# f28p551x_cpu_sys_regs register map
Vendor: Texas Instruments
Peripheral module from a debugger description file (folder C2000).
Address unit: 16 bits
Registers are 32-bit, read-write, no defined reset value unless marked. A register's access mark holds for its fields unless they carry their own. Offsets are as the file gives them; lines under a group give offsets from that group; [hi:lo] are bit positions; {n}, {i} and the like mark numbered series; 'fields as' and 'values as' point back to an identical list; <NAME> marks a mode.

## CPU_SYS_REGS — CPU SYS Registers
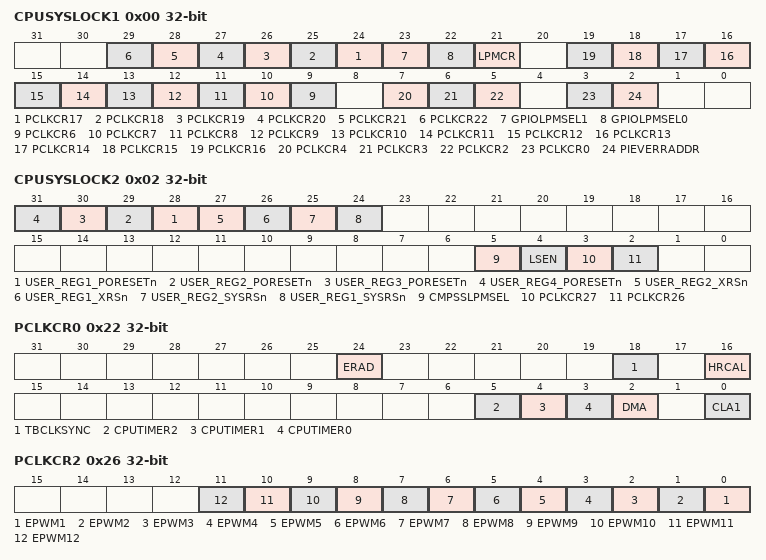
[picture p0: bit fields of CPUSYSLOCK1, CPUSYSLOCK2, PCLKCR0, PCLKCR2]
0x00 CPUSYSLOCK1 — Lock bit for CPUSYS registers
  [n+7] PCLKCR{n} (n=17..22) — Lock bit for PCLKCR{n} Register
  [23] GPIOLPMSEL1 — Lock bit for GPIOLPMSEL1 Register
  [22] GPIOLPMSEL0 — Lock bit for GPIOLPMSEL0 Register
  [21] LPMCR — Lock bit for LPMCR Register
  [n+3] PCLKCR{n} (n=6..16) — Lock bit for PCLKCR{n} Register
  [7] PCLKCR4 — Lock bit for PCLKCR4 Register
  [6] PCLKCR3 — Lock bit for PCLKCR3 Register
  [5] PCLKCR2 — Lock bit for PCLKCR2 Register
  [3] PCLKCR0 — Lock bit for PCLKCR0 Register
  [2] PIEVERRADDR — Lock bit for PIEVERRADDR Register
0x02 CPUSYSLOCK2 — Lock bit for CPUSYS registers
  [n+27] USER_REG{n}_PORESETn (n=1..4) — Lock bit for USER_REG{n}_PORESETn
  [27] USER_REG2_XRSn — Lock bit for USER_REG2_XRSn
  [26] USER_REG1_XRSn — Lock bit for USER_REG1_XRSn
  [25] USER_REG2_SYSRSn — Lock bit for USER_REG2_SYSRSn
  [24] USER_REG1_SYSRSn — Lock bit for USER_REG1_SYSRSn
  [5] CMPSSLPMSEL — Lock bit for CMPSSLPMSEL register
  [4] LSEN — Lock bit for LSEN Register
  [3] PCLKCR27 — Lock bit for PCLKCR27 Register
  [2] PCLKCR26 — Lock bit for PCLKCR26 Register
0x0A PIEVERRADDR — PIE Vector Fetch Error Address register
  [21:0] ADDR — PIE Vector Fetch Error Handler Routine Address
0x22 PCLKCR0 — Peripheral Clock Gating Registers
  [24] ERAD — ERAD module clock enable
  [18] TBCLKSYNC — EPWM Time Base Clock sync
  [16] HRCAL — HRCAL Clock Enable Bit
  [5] CPUTIMER2 — CPUTIMER2 Clock Enable bit
  [4] CPUTIMER1 — CPUTIMER1 Clock Enable bit
  [3] CPUTIMER0 — CPUTIMER0 Clock Enable bit
  [2] DMA — DMA Clock Enable bit
  [0] CLA1 — CLA1 Clock Enable Bit
0x26 PCLKCR2 — Peripheral Clock Gating Register - ETPWM
  [n-1] EPWM{n} (n=1..12) — EPWM{n} Clock Enable bit
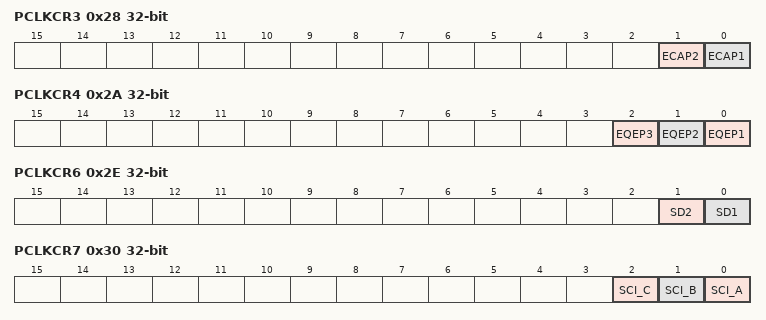
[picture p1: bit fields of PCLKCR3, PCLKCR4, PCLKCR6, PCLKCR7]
0x28 PCLKCR3 — Peripheral Clock Gating Register - ECAP
  [1] ECAP2 — ECAP2 Clock Enable bit
  [0] ECAP1 — ECAP1 Clock Enable bit
0x2A PCLKCR4 — Peripheral Clock Gating Register - EQEP
  [2] EQEP3 — EQEP3 Clock Enable bit
  [1] EQEP2 — EQEP2 Clock Enable bit
  [0] EQEP1 — EQEP1 Clock Enable bit
0x2E PCLKCR6 — Peripheral Clock Gating Register - SDFM
  [1] SD2 — SD2 Clock Enable bit
  [0] SD1 — SD1 Clock Enable bit
0x30 PCLKCR7 — Peripheral Clock Gating Register - SCI
  [2] SCI_C — SCI_C Clock Enable bit
  [1] SCI_B — SCI_B Clock Enable bit
  [0] SCI_A — SCI_A Clock Enable bit
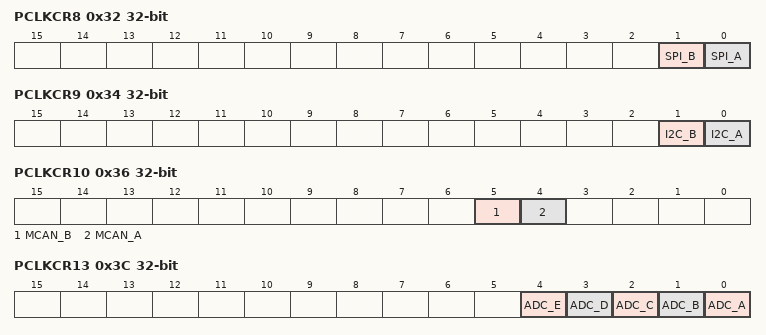
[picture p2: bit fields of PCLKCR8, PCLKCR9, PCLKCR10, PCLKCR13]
0x32 PCLKCR8 — Peripheral Clock Gating Register - SPI
  [1] SPI_B — SPI_B Clock Enable bit
  [0] SPI_A — SPI_A Clock Enable bit
0x34 PCLKCR9 — Peripheral Clock Gating Register - I2C
  [1] I2C_B — I2C_B Clock Enable bit
  [0] I2C_A — I2C_A Clock Enable bit
0x36 PCLKCR10 — Peripheral Clock Gating Register - CAN
  [5] MCAN_B — MCAN_B Clock Enable bit
  [4] MCAN_A — MCAN_A Clock Enable bit
0x38 PCLKCR11 — Peripheral Clock Gating Register - McBSP_USB
  [16] USB_A — USB_A Clock Enable bit
0x3A PCLKCR12 — Peripheral Clock Gating Register - Upp
  [0] NPU — NPU Clock Enable bit
0x3C PCLKCR13 — Peripheral Clock Gating Register - ADC
  [4] ADC_E — ADC_E Clock Enable bit
  [3] ADC_D — ADC_D Clock Enable bit
  [2] ADC_C — ADC_C Clock Enable bit
  [1] ADC_B — ADC_B Clock Enable bit
  [0] ADC_A — ADC_A Clock Enable bit
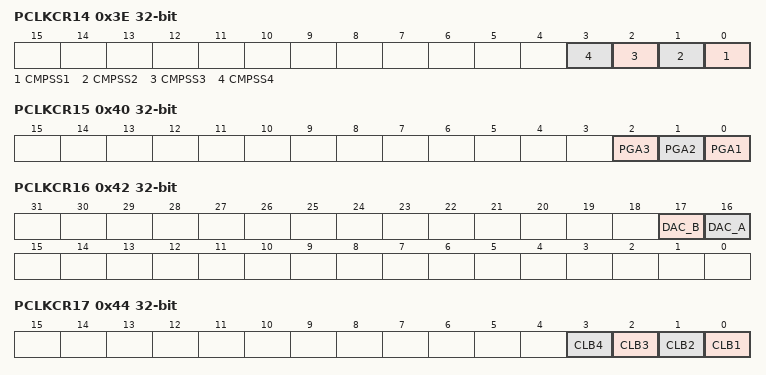
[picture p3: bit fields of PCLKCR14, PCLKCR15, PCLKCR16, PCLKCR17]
0x3E PCLKCR14 — Peripheral Clock Gating Register - CMPSS
  [n-1] CMPSS{n} (n=1..4) — CMPSS{n} Clock Enable bit
0x40 PCLKCR15 — Peripheral Clock Gating Register - PGA
  [2] PGA3 — PGA3 Clock Enable bit
  [1] PGA2 — PGA2 Clock Enable bit
  [0] PGA1 — PGA1 Clock Enable bit
0x42 PCLKCR16 — Peripheral Clock Gating Register Buf_DAC
  [17] DAC_B — Buffered_DAC_B Clock Enable Bit
  [16] DAC_A — Buffered_DAC_A Clock Enable Bit
0x44 PCLKCR17 — Peripheral Clock Gating Register - CLB
  [n-1] CLB{n} (n=1..4) — CLB{n} Clock Enable bit
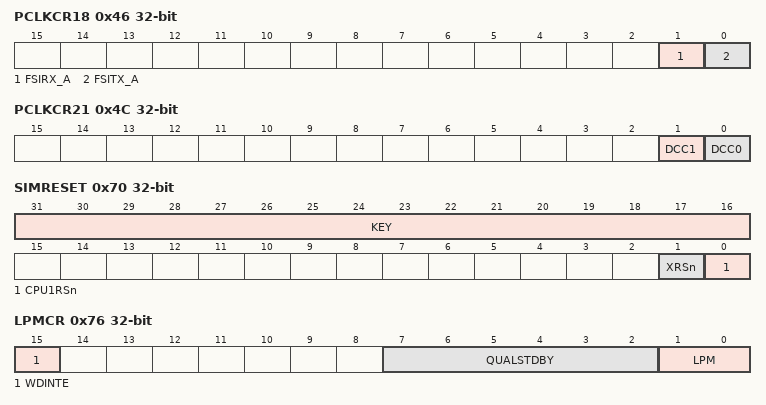
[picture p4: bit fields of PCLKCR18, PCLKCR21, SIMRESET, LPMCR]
0x46 PCLKCR18 — Peripheral Clock Gating Register - FSI
  [1] FSIRX_A — FSIRX_A Clock Enable bit
  [0] FSITX_A — FSITX_A Clock Enable bit
0x48 PCLKCR19 — Peripheral Clock Gating Register - LIN
  [0] LIN_A — LIN_A Clock Enable bit
0x4A PCLKCR20 — Peripheral Clock Gating Register - PMBUS
  [0] PMBUS_A — PMBUS_A Clock Enable bit
0x4C PCLKCR21 — Peripheral Clock Gating Register - DCC
  [1] DCC1 — DCC1 Clock Enable Bit
  [0] DCC0 — DCC0 Clock Enable Bit
0x56 PCLKCR26 — Peripheral Clock Gating Register - AES
  [0] AESA — AESA Clock Enable Bit
0x58 PCLKCR27 — Peripheral Clock Gating Register - EPG
  [0] EPG1 — EPG1 Clock Enable Bit
0x70 SIMRESET — Simulated Reset Register
  [31:16] KEY — Key value to enable write
  [1] XRSn — Generates a simulated XRSn
  [0] CPU1RSn — Generates a reset to CPU
0x76 LPMCR — LPM Control Register
  [15] WDINTE — Enable for WDINT wakeup from STANDBY
  [7:2] QUALSTDBY — STANDBY Wakeup Pin Qualification Setting
  [1:0] LPM — Low Power Mode setting
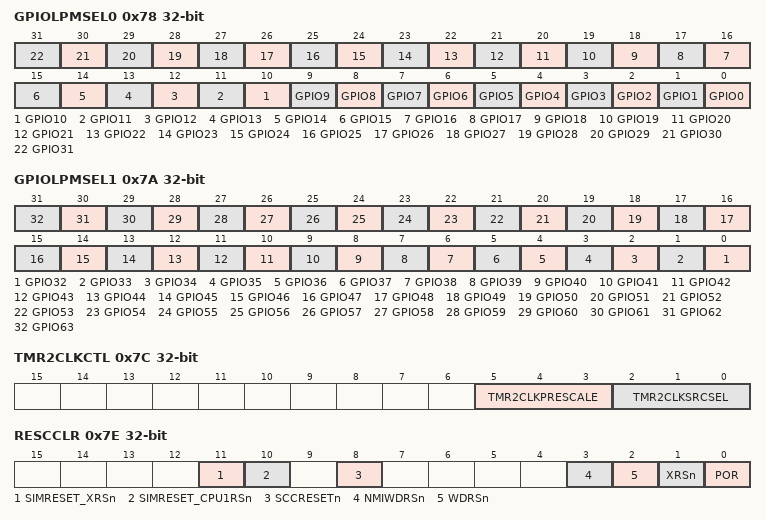
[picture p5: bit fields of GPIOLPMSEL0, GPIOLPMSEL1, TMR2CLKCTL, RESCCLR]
0x78 GPIOLPMSEL0 — GPIO LPM Wakeup select registers
  [n] GPIO{n} (n=0..31) — GPIO{n} Enable for LPM Wakeup
0x7A GPIOLPMSEL1 — GPIO LPM Wakeup select registers
  [n-32] GPIO{n} (n=32..63) — GPIO{n} Enable for LPM Wakeup
0x7C TMR2CLKCTL — Timer2 Clock Measurement functionality control register
  [5:3] TMR2CLKPRESCALE — CPU Timer 2 Clock Pre-Scale Value
  [2:0] TMR2CLKSRCSEL — CPU Timer 2 Clock Source Select Bit
0x7E RESCCLR — Reset Cause Clear Register
  [11] SIMRESET_XRSn — SIMRESET_XRSn Reset Cause Indication Bit
  [10] SIMRESET_CPU1RSn — SIMRESET_CPU1RSn Reset Cause Indication Bit
  [8] SCCRESETn — SCCRESETn Reset Cause Indication Bit
  [3] NMIWDRSn — NMIWDRSn Reset Cause Indication Bit
  [2] WDRSn — WDRSn Reset Cause Indication Bit
  [1] XRSn — XRSn Reset Cause Indication Bit
  [0] POR — POR Reset Cause Indication Bit
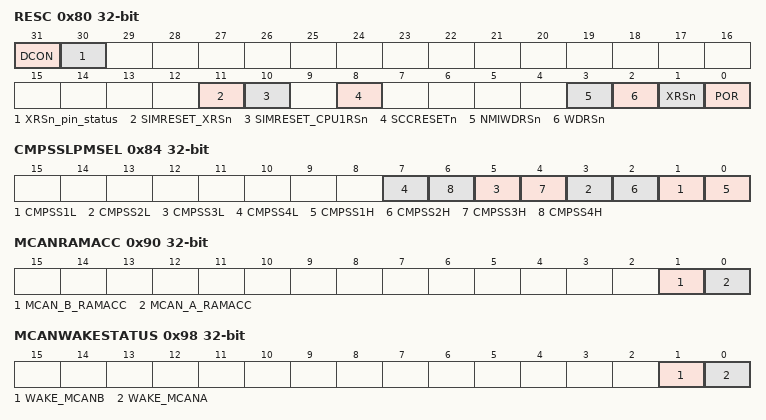
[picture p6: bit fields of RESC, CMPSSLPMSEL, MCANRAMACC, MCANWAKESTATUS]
0x80 RESC ro — Reset Cause register
  [31] DCON — Debugger conntion status to C28x
  [30] XRSn_pin_status
  [11] SIMRESET_XRSn — SIMRESET_XRSn Reset Cause Indication Bit
  [10] SIMRESET_CPU1RSn — SIMRESET_CPU1RSn Reset Cause Indication Bit
  [8] SCCRESETn — SCCRESETn Reset Cause Indication Bit
  [3] NMIWDRSn — NMIWDRSn Reset Cause Indication Bit
  [2] WDRSn — WDRSn Reset Cause Indication Bit
  [1] XRSn — XRSn Reset Cause Indication Bit
  [0] POR — POR Reset Cause Indication Bit
0x84 CMPSSLPMSEL — CMPSS LPM Wakeup select registers
  [2n-1] CMPSS{n}L (n=1..4) — CMPSS{n}L Enable for LPM Wakeup
  [2n-2] CMPSS{n}H (n=1..4) — CMPSS{n}H Enable for LPM Wakeup
0x90 MCANRAMACC — MCAN RAM access control Register
  [1] MCAN_B_RAMACC — MCAN_B_RAMACC Message RAM access control Bit
  [0] MCAN_A_RAMACC — MCAN_A_RAMACC Message RAM access control Bit
0x98 MCANWAKESTATUS ro
  [1] WAKE_MCANB — MCANB Wake Status
  [0] WAKE_MCANA — MCANA Wake Status
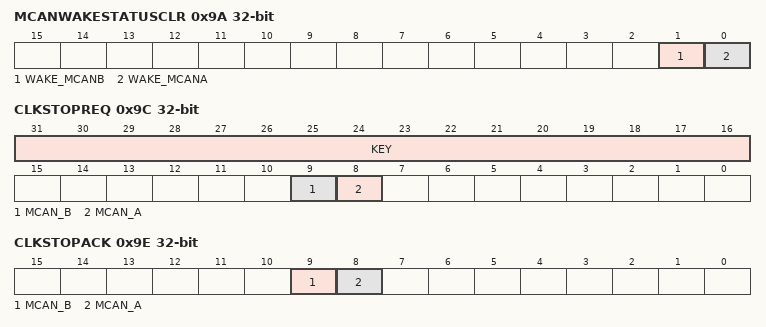
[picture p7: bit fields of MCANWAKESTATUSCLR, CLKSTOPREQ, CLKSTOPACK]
0x9A MCANWAKESTATUSCLR — MCAN Wake Status Clear Register
  [1] WAKE_MCANB — Cear bit for MCANWAKESTATUS.WAKE_MCANB bit
  [0] WAKE_MCANA — Cear bit for MCANWAKESTATUS.WAKE_MCANA bit
0x9C CLKSTOPREQ — Peripheral Clock Stop Request Register
  [31:16] KEY — Key for register write
  [9] MCAN_B — MCAN_B Clock Stop Request Bit
  [8] MCAN_A — MCAN_A Clock Stop Request Bit
0x9E CLKSTOPACK ro — Peripheral Clock Stop Ackonwledge Register
  [9] MCAN_B — MCAN_B Clock Stop Ack Bit
  [8] MCAN_A — MCAN_A Clock Stop Ack Bit
0xA0 USER_REG1_SYSRSn — Software Configurable registers reset by SYSRSn
  [31:0] BITS — SW configurable bits
0xA2 USER_REG2_SYSRSn — Software Configurable registers reset by SYSRSn
  [31:0] BITS — SW configurable bits
0xA4 USER_REG1_XRSn — Software Configurable registers reset by XRSn
  [31:0] BITS — SW configurable bits
0xA6 USER_REG2_XRSn — Software Configurable registers reset by XRSn
  [31:0] BITS — SW configurable bits
{0xA6+2i} USER_REG{i}_PORESETn (i=1..4) — Software Configurable registers reset by PORESETn
  [31:0] BITS — SW configurable bits
0xB0 JTAG_MMR_REG access not given — Readback of JTAG registers for test purpose
